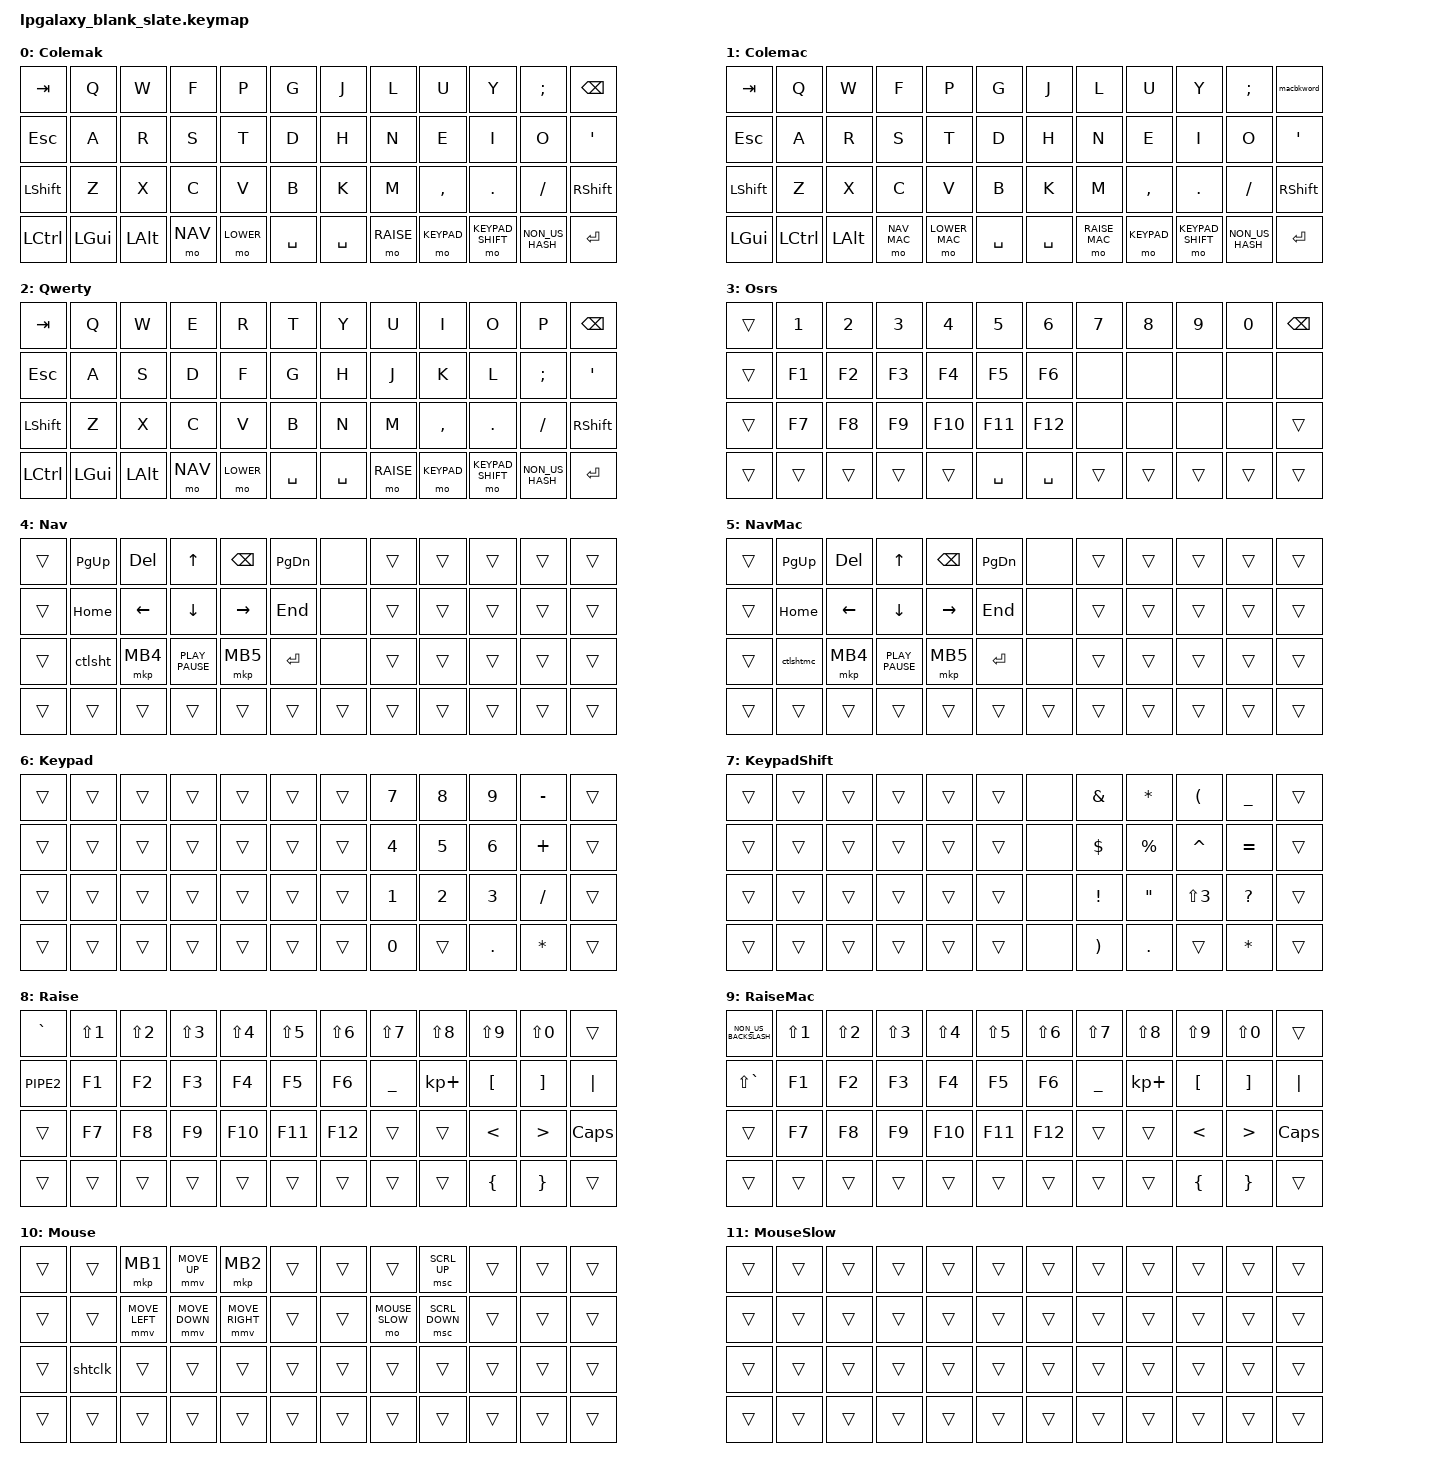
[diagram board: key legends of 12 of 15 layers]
/*
 * Copyright (c) 2022 Pete Johanson
 *
 * SPDX-License-Identifier: MIT
 */

#define ZMK_POINTING_DEFAULT_MOVE_VAL 2500  // default: 600
#define ZMK_POINTING_DEFAULT_SCRL_VAL 20    // default: 10

#include <behaviors.dtsi>
#include <dt-bindings/zmk/keys.h>
#include <dt-bindings/zmk/bt.h>
#include <dt-bindings/zmk/outputs.h>
#include <dt-bindings/zmk/pointing.h>
#include <input/processors.dtsi>


// Layers
#define COLEMAK 0
#define COLEMAC 1
#define QWERTY 2
#define OSRS 3
#define NAV 4
#define NAV_MAC 5
#define KEYPAD 6
#define KEYPAD_SHIFT 7
#define RAISE 8
#define RAISE_MAC 9
#define MOUSE 10
#define MOUSE_SLOW 11
#define LOWER 12
#define LOWER_MAC 13
#define ADJUST 14

// Using layer taps on thumbs, having quick tap as well helps w/ repeating space/backspace
&lt { quick_tap_ms = <200>; };

&mmv_input_listener {
    snipe-mode {
        layers = <MOUSE_SLOW>;
        input-processors = <&zip_xy_scaler 1 4>;
    };
};

/ {
    chosen {
       zmk,physical-layout = &layout_ortho_4x12_all1u;
    };

    behaviors {
        macbkword: macbkword {
            compatible = "zmk,behavior-mod-morph";
            #binding-cells = <0>;
            bindings = <&kp BSPC>, <&kp LA(BSPC)>;
            mods = <(MOD_LGUI)>;
        };
    };

    macros {
        ctlsht: ctlsht {
            compatible = "zmk,behavior-macro";
            #binding-cells = <0>;
            bindings
                = <&macro_press &kp LSHFT>
                , <&macro_press &kp LCTRL>
                , <&macro_pause_for_release>
                , <&macro_release &kp LCTRL>
                , <&macro_release &kp LSHFT>
                ;
        };
        ctlshtmc: ctlshtmc {
            compatible = "zmk,behavior-macro";
            #binding-cells = <0>;
            bindings
                = <&macro_press &kp LSHFT>
                , <&macro_press &kp LALT>
                , <&macro_pause_for_release>
                , <&macro_release &kp LALT>
                , <&macro_release &kp LSHFT>
                ;
        };
        shtclk: shtclk {
            compatible = "zmk,behavior-macro";
            #binding-cells = <0>;
            bindings
                = <&macro_press &kp LSHFT>
                , <&macro_press &mkp LCLK>
                , <&macro_pause_for_release>
                , <&macro_release &mkp LCLK>
                , <&macro_release &kp LSHFT>
                ;
        };
    };
    
    conditional_layers {
        compatible = "zmk,conditional-layers";
        low_raise {
            if-layers = <LOWER RAISE>;
            then-layer = <ADJUST>;
        };
        mac_low_raise {
            if-layers = <LOWER_MAC RAISE_MAC>;
            then-layer = <ADJUST>;
        };
        nav_raise {
            if-layers = <NAV RAISE>;
            then-layer = <MOUSE>;
        };
        mac_nav_raise {
            if-layers = <NAV_MAC RAISE_MAC>;
            then-layer = <MOUSE>;
        };
    };

    keymap {
        compatible = "zmk,keymap";

        colemak_layer {
            label = "Colemak";
            bindings = <
 &kp TAB    &kp Q      &kp W      &kp F       &kp P          &kp G          &kp J            &kp L          &kp U       &kp Y            &kp SEMI        &kp BKSP
 &kp ESC    &kp A      &kp R      &kp S       &kp T          &kp D          &kp H            &kp N          &kp E       &kp I            &kp O           &kp QUOT
 &kp LSHFT  &kp Z      &kp X      &kp C       &kp V          &kp B          &kp K            &kp M          &kp COMMA   &kp DOT          &kp FSLH        &kp RSHFT
 &kp LCTRL  &kp LGUI   &kp LALT   &mo NAV     &mo LOWER      &kp SPACE      &kp SPACE        &mo RAISE      &mo KEYPAD  &mo KEYPAD_SHIFT &kp NON_US_HASH &kp RET
            >;
        };
        colemac_layer {
            label = "Colemac";
            bindings = <
 &kp TAB            &kp Q      &kp W      &kp F       &kp P          &kp G          &kp J            &kp L          &kp U       &kp Y            &kp SEMI        &macbkword
 &kp ESC            &kp A      &kp R      &kp S       &kp T          &kp D          &kp H            &kp N          &kp E       &kp I            &kp O           &kp QUOT
 &kp LSHFT          &kp Z      &kp X      &kp C       &kp V          &kp B          &kp K            &kp M          &kp COMMA   &kp DOT          &kp FSLH        &kp RSHFT
 &kp LGUI           &kp LCTRL  &kp LALT   &mo NAV_MAC &mo LOWER_MAC  &kp SPACE      &kp SPACE        &mo RAISE_MAC  &mo KEYPAD  &mo KEYPAD_SHIFT &kp NON_US_HASH &kp RET
            >;
        };
        qwerty_layer {
            label = "Qwerty";
            bindings = <
 &kp TAB    &kp Q      &kp W      &kp E       &kp R          &kp T          &kp Y            &kp U          &kp I       &kp O            &kp P           &kp BKSP
 &kp ESC    &kp A      &kp S      &kp D       &kp F          &kp G          &kp H            &kp J          &kp K       &kp L            &kp SEMI        &kp QUOT
 &kp LSHFT  &kp Z      &kp X      &kp C       &kp V          &kp B          &kp N            &kp M          &kp COMMA   &kp DOT          &kp FSLH        &kp RSHFT
 &kp LCTRL  &kp LGUI   &kp LALT   &mo NAV     &mo LOWER      &kp SPACE      &kp SPACE        &mo RAISE      &mo KEYPAD  &mo KEYPAD_SHIFT &kp NON_US_HASH &kp RET
            >;
        };
        osrs_layer {
            label = "Osrs";
            bindings = <
 &trans     &kp N1     &kp N2     &kp N3      &kp N4         &kp N5         &kp N6           &kp N7         &kp N8      &kp N9        &kp N0        &kp BKSP
 &trans     &kp F1     &kp F2     &kp F3      &kp F4         &kp F5         &kp F6           &none          &none       &none         &none         &none 
 &trans     &kp F7     &kp F8     &kp F9      &kp F10        &kp F11        &kp F12          &none          &none       &none         &none         &trans  
 &trans     &trans     &trans     &trans      &trans         &kp SPACE      &kp SPACE        &trans         &trans      &trans        &trans        &trans  
            >;
        };
        nav_layer {
            label = "Nav";
            bindings = <
 &trans     &kp PG_UP  &kp DEL    &kp UP           &kp BKSP       &kp PG_DN      &none            &trans         &trans      &trans        &trans        &trans
 &trans     &kp HOME   &kp LEFT   &kp DOWN         &kp RIGHT      &kp END        &none            &trans         &trans      &trans        &trans        &trans
 &trans     &ctlsht    &mkp MB4   &kp K_PLAY_PAUSE &mkp MB5       &kp RET        &none            &trans         &trans      &trans        &trans        &trans
 &trans     &trans     &trans     &trans           &trans         &trans         &trans           &trans         &trans      &trans        &trans        &trans
            >;
        };
        nav_mac_layer {
            label = "NavMac";
            bindings = <
 &trans     &kp PG_UP  &kp DEL    &kp UP           &kp BKSP       &kp PG_DN      &none            &trans         &trans      &trans        &trans        &trans
 &trans     &kp HOME   &kp LEFT   &kp DOWN         &kp RIGHT      &kp END        &none            &trans         &trans      &trans        &trans        &trans
 &trans     &ctlshtmc  &mkp MB4   &kp K_PLAY_PAUSE &mkp MB5       &kp RET        &none            &trans         &trans      &trans        &trans        &trans
 &trans     &trans     &trans     &trans           &trans         &trans         &trans           &trans         &trans      &trans        &trans        &trans
            >;
        };
        keypad_layer {
            label = "Keypad";
            bindings = <
 &trans     &trans     &trans     &trans      &trans         &trans         &trans           &kp N7         &kp N8      &kp N9        &kp MINUS       &trans
 &trans     &trans     &trans     &trans      &trans         &trans         &trans           &kp N4         &kp N5      &kp N6        &kp PLUS        &trans
 &trans     &trans     &trans     &trans      &trans         &trans         &trans           &kp N1         &kp N2      &kp N3        &kp FSLH        &trans
 &trans     &trans     &trans     &trans      &trans         &trans         &trans           &kp N0         &trans      &kp DOT       &kp STAR        &trans
            >;
        };
        keypad_shift_layer {
            label = "KeypadShift";
            bindings = <
 &trans     &trans     &trans     &trans      &trans         &trans         &none           &kp AMPS       &kp STAR    &kp LPAR      &kp UNDER       &trans
 &trans     &trans     &trans     &trans      &trans         &trans         &none           &kp DLLR       &kp PRCNT   &kp CARET     &kp EQUAL       &trans
 &trans     &trans     &trans     &trans      &trans         &trans         &none           &kp EXCL       &kp DQT     &kp LS(N3)    &kp QMARK       &trans
 &trans     &trans     &trans     &trans      &trans         &trans         &none           &kp RPAR       &kp DOT     &trans        &kp STAR        &trans
            >;
        };
        raise_layer {
            label = "Raise";
            bindings = <
 &kp GRAVE  &kp LS(N1) &kp LS(N2) &kp LS(N3)  &kp LS(N4)     &kp LS(N5)     &kp LS(N6)      &kp LS(N7)     &kp LS(N8)  &kp LS(N9)    &kp LS(N0)      &trans
 &kp PIPE2  &kp F1     &kp F2     &kp F3      &kp F4         &kp F5         &kp F6          &kp UNDER      &kp KP_PLUS &kp LBKT      &kp RBKT        &kp PIPE
 &trans     &kp F7     &kp F8     &kp F9      &kp F10        &kp F11        &kp F12         &trans         &trans      &kp LT        &kp GT          &kp CAPS
 &trans     &trans     &trans     &trans      &trans         &trans         &trans          &trans         &trans      &kp LBRC      &kp RBRC        &trans
            >;
        };
        raise_mac_layer {
            label = "RaiseMac";
            bindings = <
 &kp NON_US_BACKSLASH &kp LS(N1) &kp LS(N2) &kp LS(N3)  &kp LS(N4)     &kp LS(N5)     &kp LS(N6)      &kp LS(N7)     &kp LS(N8)  &kp LS(N9)    &kp LS(N0)      &trans
 &kp LS(GRAVE)        &kp F1     &kp F2     &kp F3      &kp F4         &kp F5         &kp F6          &kp UNDER      &kp KP_PLUS &kp LBKT      &kp RBKT        &kp PIPE
 &trans               &kp F7     &kp F8     &kp F9      &kp F10        &kp F11        &kp F12         &trans         &trans      &kp LT        &kp GT          &kp CAPS
 &trans               &trans     &trans     &trans      &trans         &trans         &trans          &trans         &trans      &kp LBRC      &kp RBRC        &trans
            >;
        };
        mouse_layer {
            label = "Mouse";
            bindings = <
 &trans     &trans     &mkp MB1       &mmv MOVE_UP    &mkp MB2         &trans         &trans           &trans         &msc SCRL_UP   &trans        &trans        &trans
 &trans     &trans     &mmv MOVE_LEFT &mmv MOVE_DOWN  &mmv MOVE_RIGHT  &trans         &trans           &mo MOUSE_SLOW &msc SCRL_DOWN &trans        &trans        &trans    
 &trans     &shtclk    &trans         &trans          &trans           &trans         &trans           &trans         &trans         &trans        &trans        &trans    
 &trans     &trans     &trans         &trans          &trans           &trans         &trans           &trans         &trans         &trans        &trans        &trans    
            >;
        };
        mouse_slow_layer {
            label = "MouseSlow";
            bindings = <
 &trans     &trans     &trans       &trans          &trans           &trans         &trans           &trans         &trans   &trans        &trans        &trans
 &trans     &trans     &trans       &trans          &trans           &trans         &trans           &trans         &trans   &trans        &trans        &trans    
 &trans     &trans     &trans       &trans          &trans           &trans         &trans           &trans         &trans   &trans        &trans        &trans    
 &trans     &trans     &trans       &trans          &trans           &trans         &trans           &trans         &trans   &trans        &trans        &trans    
            >;
        };
        lower_layer {
            label = "Lower";
            bindings = <
 &kp GRAVE            &kp N1     &kp N2     &kp N3      &kp N4         &kp N5         &kp N6          &kp N7         &kp N8      &kp N9        &kp N0          &trans
 &kp NON_US_BACKSLASH &kp F1     &kp F2     &kp F3      &kp F4         &kp F5         &kp F6          &kp MINUS      &kp EQUAL   &trans        &trans          &trans
 &trans               &kp F7     &kp F8     &kp F9      &kp F10        &kp F11        &kp F12         &trans         &trans      &trans        &trans          &kp CAPS
 &trans               &trans     &trans     &trans      &trans         &trans         &trans          &trans         &trans      &trans        &trans          &trans
            >;
        };
        lower_mac_layer {
            label = "LowerMac";
            bindings = <
 &kp NON_US_BACKSLASH   &kp N1     &kp N2     &kp N3      &kp N4         &kp N5         &kp N6          &kp N7         &kp N8      &kp N9        &kp N0          &trans
 &kp GRAVE              &kp F1     &kp F2     &kp F3      &kp F4         &kp F5         &kp F6          &kp MINUS      &kp EQUAL   &trans        &trans          &trans
 &trans                 &kp F7     &kp F8     &kp F9      &kp F10        &kp F11        &kp F12         &trans         &trans      &trans        &trans          &kp CAPS
 &trans                 &trans     &trans     &trans      &trans         &trans         &trans          &trans         &trans      &trans        &trans          &trans
            >;
        };
        adjust_layer {
            label = "Adjust";
            bindings = <
 &out OUT_TOG &bt BT_SEL 1 &bt BT_SEL 2 &bt BT_SEL 3 &bt BT_SEL 4  &bt BT_SEL 5   &trans           &trans         &trans      &trans        &trans        &trans
 &bt BT_CLR   &trans       &trans       &trans       &trans        &trans         &trans           &to QWERTY     &to COLEMAK &trans        &trans        &trans    
 &sys_reset   &trans       &trans       &trans       &trans        &trans         &trans           &to OSRS       &to COLEMAC &trans        &trans        &trans    
 &bootloader  &trans       &trans       &trans       &trans        &trans         &trans           &trans         &trans      &trans        &trans        &trans    
            >;
        };
    };
};

